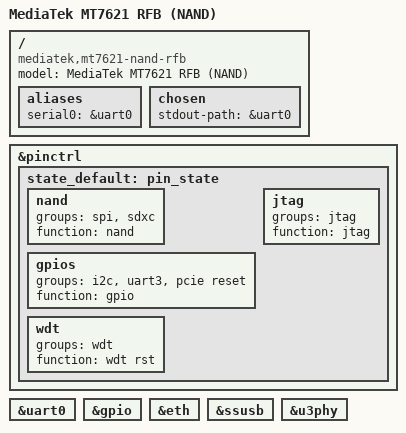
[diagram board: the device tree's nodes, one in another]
// SPDX-License-Identifier: GPL-2.0
/*
 * Copyright (C) 2022 MediaTek Inc. All rights reserved.
 *
 * Author: Weijie Gao <weijie.gao@mediatek.com>
 */

/dts-v1/;

#include "mt7621.dtsi"

/ {
	compatible = "mediatek,mt7621-nand-rfb", "mediatek,mt7621-soc";
	model = "MediaTek MT7621 RFB (NAND)";

	aliases {
		serial0 = &uart0;
	};

	chosen {
		stdout-path = &uart0;
	};
};

&pinctrl {
	state_default: pin_state {
		nand {
			groups = "spi", "sdxc";
			function = "nand";
		};

		gpios {
			groups = "i2c", "uart3", "pcie reset";
			function = "gpio";
		};

		wdt {
			groups = "wdt";
			function = "wdt rst";
		};

		jtag {
			groups = "jtag";
			function = "jtag";
		};
	};
};

&uart0 {
	status = "okay";
};

&gpio {
	status = "okay";
};

&eth {
	status = "okay";
};

&ssusb {
	status = "okay";
};

&u3phy {
	status = "okay";
};
